# EG32M0x register map
Vendor: EGmicro Ltd.; Series: EG32M0x; File version: 1.0
EGmicro 32-bit Cortex-M0 Microcontroller based device, CPU clock up to 72MHz, etc.
CPU: CM0 r0p0, little endian, no MPU, no FPU, 3 interrupt priority bits
Registers are 32-bit, read-write, reset 0x0 unless marked. A register's access mark holds for its fields unless they carry their own. Offsets are from the block's base; lines under a group give offsets from that group; [hi:lo] are bit positions; {n}, {i} and the like mark numbered series; 'fields as' and 'values as' point back to an identical list; <NAME> marks a mode.

## Memory map
0x40020000 SYSTEM size 0x80 — SYSTEM unit
0x400200A0 GPIOA size 0x40 — GPIOA unit
0x400200E0 GPIOB size 0x40 — GPIOB unit
0x40020120 POWER_MAN size 0x10 — POWER MANAGEMENT unit
0x40020140 ADC size 0x50 — ADC unit
0x40020190 WDT size 0x10 — WDT unit
0x400201A0 WWDG size 0x10 — WWDG unit
0x400201B0 GPIOC size 0x40 — GPIOC unit
0x40020210 CRC size 0x20 — CRC unit
0x40020240 FLASH size 0x50 — FLASH unit
0x40020290 UART0 size 0x10 — UART0 unit
0x400202A0 UART1 size 0x10 — UART1 unit
0x400202C0 SPI size 0x20 — SPI unit
0x400202E0 IIC size 0x20 — IIC unit
0x40020310 TIMER7 size 0x30 — TIMER7 unit
0x40020370 COMP0 size 0x10 — COMP0 unit
0x40020380 COMP1 size 0x10 — COMP1 unit
0x40020390 OPAM0 size 0x8 — OPAM0 unit
0x40020398 OPAM1 size 0x8 — OPAM1 unit
0x400203A0 HWDIV size 0x20 — HWDIV unit
0x40020400 TIMER1 size 0x60 — TIMER1 unit
0x40020460 TIMER2 size 0x60 — TIMER2 unit
0x400204C0 TIMER3 size 0x60 — TIMER3 unit
0x40020520 TIMER4 size 0x60 — TIMER4 unit
0x40020580 TIMER5 size 0x60 — TIMER5 unit
0x400205E0 TIMER6 size 0x60 — TIMER6 unit
0x40030000 DMA size 0x200 — DMA unit

## FLASH — FLASH unit
Base 0x40020240
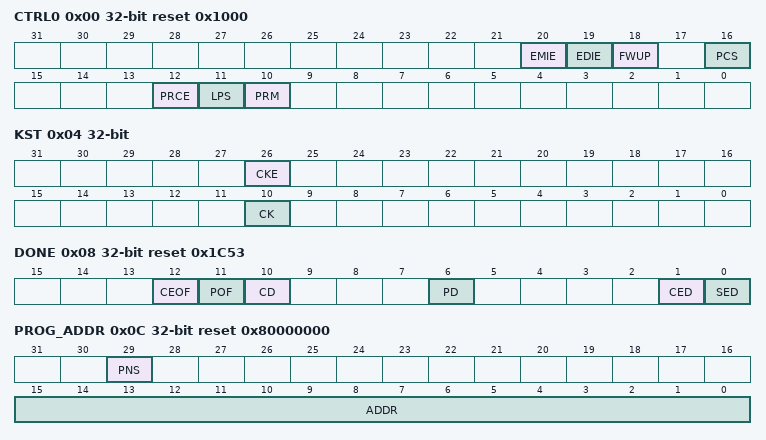
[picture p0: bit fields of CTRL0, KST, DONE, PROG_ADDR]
0x00 CTRL0 reset 0x1000
  [20] EMIE — multiple bit error interrpution enable
  [19] EDIE — one bit error interrpution enable
  [18] FWUP — EFLASH fast wake-up enable
  [16] PCS — FLASH burning clock source selection
  [12] PRCE — Add CRC value at the end when moving RAM data to FLASH
  [11] LPS — Is it allowed to interrupt FLASH programming and erase except
  [10] PRM — Directly write RAM data to FLASH
0x04 KST
  [26] CKE — CRC trigger enable of FLASH
  [10] CK — CRC check trigger of FLASH
0x08 DONE reset 0x1C53
  [12] CEOF — Chip erases results
  [11] POF — As a result of programming
  [10] CD — CRC completion flag of FLASH
  [6] PD — End of program flag
  [1] CED — The Main field is fully erased
  [0] SED — Sector erase flag
0x0C PROG_ADDR reset 0x80000000
  [29] PNS — Choose MAIN/NVR as the programming address
  [15:0] ADDR — FLASH programming logical address
0x10 PROG_DATA
  [31:0] DATA — Configure PROG_DATA to start programming or display data when going to FLASH programming
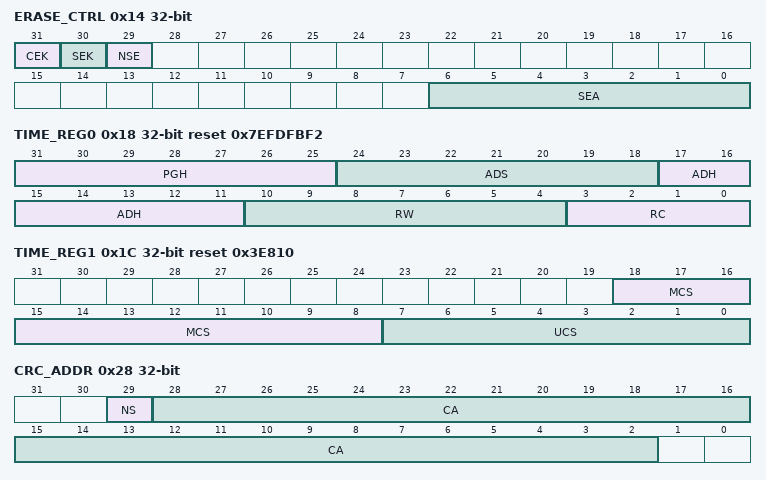
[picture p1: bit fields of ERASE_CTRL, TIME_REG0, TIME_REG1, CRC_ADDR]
0x14 ERASE_CTRL
  [31] CEK — Trigger for Chip erase
  [30] SEK — Trigger for sector erase
  [29] NSE — Sector enable bit of the NVR
  [6:0] SEA — Erase the sector selection
0x18 TIME_REG0 reset 0x7EFDFBF2
  [31:25] PGH — WE high to PROG2 high hold min time is 500ns
  [24:18] ADS — BYTE/Address/data setup min time is 500ns
  [17:11] ADH — BYTE/Address/data hold min time is 500ns
  [10:4] RW — Latency to next operation after PROG/sector ERASE low min time is 500ns
  [3:0] RC — Read flash cycle
0x1C TIME_REG1 reset 0x3E810
  [18:8] MCS — 1ms Time configuration value, in the unit of 1us
  [7:0] UCS — The clock frequency is 32MHz by default 2 frequency division
0x20 NVR_PWD
  [31:0] NPW — NVR area password
0x24 MAIN_PWD
  [31:0] MPW — MAIN area password
0x28 CRC_ADDR
  [29] NS — Whether the address is an NVR zone
  [28:2] CA — Set this parameter to the start address of the CRC check
0x2C CRC_LEN
  [16:2] CL — FLASH verifies the data length of the CRC
0x30 CRC_OUT reset 0x5A5A55AA
  [31:0] CO — CRC results
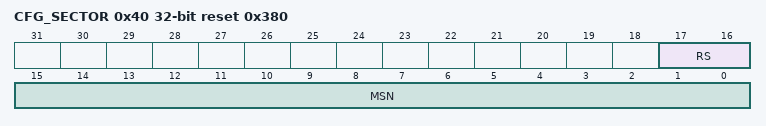
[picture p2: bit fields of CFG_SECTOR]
0x40 CFG_SECTOR reset 0x380
  [17:16] RS — Size of RAM
  [15:0] MSN — sector number of the EFLASH MAIN

## CRC — CRC unit
Base 0x40020210
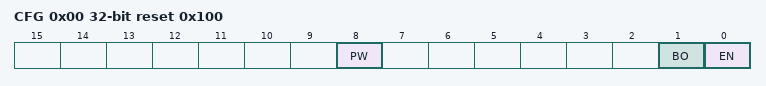
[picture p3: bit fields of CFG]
0x00 CFG reset 0x100
  [8] PW — Polynomial width
  [1] BO — Check order of input data
  [0] EN — CRC enablement
0x04 INIT reset 0xFFFFFFFF
  [31:0] INITV — CRC initial value
0x08 INV reset 0xFFFFFFFF
  [31:0] INVV — CRC output takes reverse control
0x0C POLY reset 0xEDB88320
  [31:0] PV — CRC polynomial value
0x10 STA
  [0] BUSY — CRC busy state
0x14 DATA
  [31:0] DATA — CRC data register
0x18 LEN
  [15:0] LENGTH — CRC Indicates the byte length of the verification data

## Licence text in the file
EGmicro Limited (EGmicro) is supplying this software for use with Cortex-M0!
